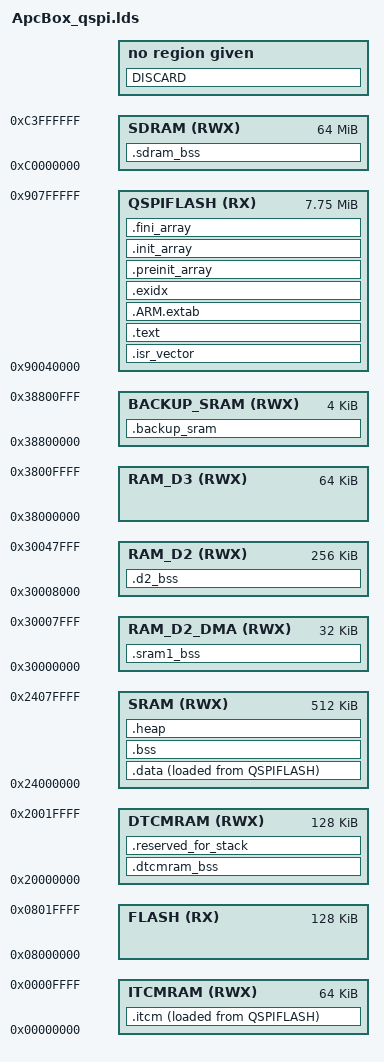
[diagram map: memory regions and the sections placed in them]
/* libDaisy's STM32H750IB_qspi.lds (v9.0.0) plus the .itcm section below. */
/* Generated by LinkerScriptGenerator [http://visualgdb.com/tools/LinkerScriptGenerator]
 * Target: STM32H750IB
 * The file is provided under the BSD license.
 * yeah okay but i also modified it a lot so like, give me some credit too mr BSD
 */

ENTRY(Reset_Handler)

MEMORY
{
	FLASH       (RX)  : ORIGIN = 0x08000000, LENGTH = 128K
	DTCMRAM     (RWX) : ORIGIN = 0x20000000, LENGTH = 128K
	SRAM        (RWX) : ORIGIN = 0x24000000, LENGTH = 512K
	RAM_D2_DMA  (RWX) : ORIGIN = 0x30000000, LENGTH = 32K
	RAM_D2      (RWX) : ORIGIN = 0x30008000, LENGTH = 256K
	RAM_D3      (RWX) : ORIGIN = 0x38000000, LENGTH = 64K
	BACKUP_SRAM (RWX) : ORIGIN = 0x38800000, LENGTH = 4K
	ITCMRAM     (RWX) : ORIGIN = 0x00000000, LENGTH = 64K
	SDRAM       (RWX) : ORIGIN = 0xc0000000, LENGTH = 64M
	QSPIFLASH   (RX)  : ORIGIN = 0x90040000, LENGTH = 7936K
}

_estack = 0x20020000;

SECTIONS
{
	.isr_vector :
	{
		. = ALIGN(4);
		KEEP(*(.isr_vector))
		. = ALIGN(4);
	} > QSPIFLASH

	/* ApcBox: what the audio callback runs, in the zero-wait code memory (ITCM)
	   and not read from the QSPI flash. The image sits in the flash and
	   ItcmLoad in main.cpp copies it down from .preinit_array, ahead of every
	   constructor. Only put here what nothing calls before that.
	   Starts 32 bytes in, so no function sits at address 0. Functions are
	   picked by section name (-ffunction-sections), nothing in the sources
	   says where they go. Must stay ahead of .text: first match wins. */
	.itcm :
	{
		. = . + 32;
		. = ALIGN(4);
		_sitcm = .;
		*main.o(.text.*AudioCallback*)
		*engine.o(.text.*6Engine7ProcessE* .text.*ProcessPerfFx* .text.*6Engine6OnStep* .text.*StartVoice*)
		*engine.o(.text.*AcidVoice* .text.*AcidStep* .text.*AcidLiveEvents* .text.*PerfFxEdges*)
		*engine.o(.text.*UpdateBlockParams* .text.*HandleRequests* .text.*StepLength* .text.*CaptureRead*)
		*engine.o(.text.*LiveHit* .text.*LiveRecStep* .text.*6Engine5Click*)
		*usbdev.o(.text.*AudioPush*)
		*libdaisy.a:audio.o(.text.*InternalCallback*)
		*libdaisy.a:sai.o(.text.*InternalCallback* .text.DMA1_Stream* .text.HAL_SAI_*Cplt*)
		*libdaisy.a:stm32h7xx_hal_sai.o(.text.SAI_DMA* .text.HAL_SAI_*Callback)
		*libdaisy.a:stm32h7xx_hal_dma.o(.text.HAL_DMA_IRQHandler)
		*libdaisy.a:sai.o(.text.*9SaiHandle9GetOffsetEv .text.*9SaiHandle9GetConfigEv)
		*libdaisy.a:system.o(.text.*6System7GetTickEv .text.*6System5GetUsEv)
		*libdaisy.a:tim.o(.text.*11TimerHandle7GetTickEv .text.*11TimerHandle5GetUsEv .text.*11TimerHandle4Impl7GetTickEv .text.*11TimerHandle4Impl5GetUsEv)
		*libdaisysp.a:svf.o(.text.*3Svf7Process* .text.*SetFreq* .text.*SetRes*)
		*engine.o(.text.*2ab6Reverb7Process* .text.*2ab6Reverb17NextRandomLineseg*)
		*(.text.expf .text.powf .text.sinf .text.cosf .text.lrintf .text.exp2f .text.sqrtf .text.__ieee754_sqrtf)
		*libm_a-k_cos.o(.text*)
		*libm_a-k_sin.o(.text*)
		. = ALIGN(4);
		_eitcm = .;
	} > ITCMRAM AT > QSPIFLASH
	/* where _sitcm's bytes sit in the flash (the section starts 32 bytes before it) */
	_siitcm = LOADADDR(.itcm) + (_sitcm - ADDR(.itcm));

	.text :
	{
		. = ALIGN(4);
		_stext = .;

		*(.text)
		*(.text*)
		*(.rodata)
		*(.rodata*)
		*(.glue_7)
		*(.glue_7t)
		KEEP(*(.init))
		KEEP(*(.fini))
		. = ALIGN(4);
		_etext = .;

	} > QSPIFLASH

	.ARM.extab :
	{
		. = ALIGN(4);
		*(.ARM.extab)
		*(.gnu.linkonce.armextab.*)
		. = ALIGN(4);
	} > QSPIFLASH

	.exidx :
	{
		. = ALIGN(4);
		PROVIDE(__exidx_start = .);
		*(.ARM.exidx*)
		. = ALIGN(4);
		PROVIDE(__exidx_end = .);
	} > QSPIFLASH

	.ARM.attributes 0 : { *(.ARM.attributes) }

	.preinit_array :
	{
		PROVIDE_HIDDEN(__preinit_array_start = .);
		KEEP(*(.preinit_array*))
		PROVIDE_HIDDEN(__preinit_array_end = .);
	} > QSPIFLASH

	.init_array :
	{
		PROVIDE_HIDDEN(__init_array_start = .);
		KEEP(*(SORT(.init_array.*)))
		KEEP(*(.init_array*))
		PROVIDE_HIDDEN(__init_array_end = .);
	} > QSPIFLASH

	.fini_array :
	{
		PROVIDE_HIDDEN(__fini_array_start = .);
		KEEP(*(.fini_array*))
		KEEP(*(SORT(.fini_array.*)))
		PROVIDE_HIDDEN(__fini_array_end = .);
	} > QSPIFLASH

	.sram1_bss (NOLOAD) :
	{
		. = ALIGN(4);
		_ssram1_bss = .;

		PROVIDE(__sram1_bss_start__ = _sram1_bss);
		*(.sram1_bss)
		*(.sram1_bss*)
		. = ALIGN(4);
		_esram1_bss = .;

		PROVIDE(__sram1_bss_end__ = _esram1_bss);
	} > RAM_D2_DMA

	.data :
	{
		. = ALIGN(4);
		_sdata = .;

		PROVIDE(__data_start__ = _sdata);
		*(.data)
		*(.data*)
		. = ALIGN(4);
		_edata = .;

		PROVIDE(__data_end__ = _edata);
	} > SRAM AT > QSPIFLASH

	_sidata = LOADADDR(.data);

	.bss (NOLOAD) :
	{
		. = ALIGN(4);
		_sbss = .;

		PROVIDE(__bss_start__ = _sbss);
		*(.bss)
		*(.bss*)
		*(COMMON)
		. = ALIGN(4);
		_ebss = .;

		PROVIDE(__bss_end__ = _ebss);
	} > SRAM

	.dtcmram_bss (NOLOAD) :
	{
		. = ALIGN(4);
		_sdtcmram_bss = .;

		PROVIDE(__dtcmram_bss_start__ = _sdtcmram_bss);
		*(.dtcmram_bss)
		*(.dtcmram_bss*)
		. = ALIGN(4);
		_edtcmram_bss = .;

		PROVIDE(__dtcmram_bss_end__ = _edtcmram_bss);
	} > DTCMRAM

	/*
	.sdram_text :
	{
		. = ALIGN(4);
		_ssdram_text = .;

		PROVIDE(__sdram_text_start = _ssdram_text);
		*(.sdram_text)
		*(.sdram_text*)
		. = ALIGN(4);
		_esdram_text = .;

		PROVIDE(__sdram_text_end = _esdram_text);
	} > SDRAM AT >FLASH
	_sisdram_text = LOADADDR(.sdram_text);
	*/

	.sdram_bss (NOLOAD) :
	{
		. = ALIGN(4);
		_ssdram_bss = .;

		PROVIDE(__sdram_bss_start = _ssdram_bss);
		*(.sdram_bss)
		*(.sdram_bss*)
		. = ALIGN(4);
		_esdram_bss = .;

		PROVIDE(__sdram_bss_end = _esdram_bss);
	} > SDRAM

	.backup_sram (NOLOAD) :
	{
		. = ALIGN(4);
		_sbackup_sram = .;

		PROVIDE(__backup_sram_start = _sbackup_sram);
		*(.backup_sram)
		*(.backup_sram*)
		. = ALIGN(4);
		_ebackup_sram = .;

		PROVIDE(__backup_sram_end = _ebackup_sram);
	} > BACKUP_SRAM


    /* .qspiflash_text :
	{
		. = ALIGN(4);
		_sqspiflash_text = .;

		PROVIDE(__qspiflash_text_start = _sqspiflash_text);
		*(.qspiflash_text)
		*(.qspiflash_text*)
		. = ALIGN(4);
		_eqspiflash_text = .;

		PROVIDE(__qspiflash_text_end = _eqspiflash_text);
	} > QSPIFLASH

	.qspiflash_data :
	{
		. = ALIGN(4);
		_sqspiflash_data = .;

		PROVIDE(__qspiflash_data_start = _sqspiflash_data);
		*(.qspiflash_data)
		*(.qspiflash_data*)
		. = ALIGN(4);
		_eqspiflash_data = .;

		PROVIDE(__qspiflash_data_end = _eqspiflash_data);
	} > QSPIFLASH

	.qspiflash_bss (NOLOAD) :
	{
		. = ALIGN(4);
		_sqspiflash_bss = .;

		PROVIDE(__qspiflash_bss_start = _sqspiflash_bss);
		*(.qspiflash_bss)
		*(.qspiflash_bss*)
		. = ALIGN(4);
		_eqspiflash_bss = .;

		PROVIDE(__qspiflash_bss_end = _eqspiflash_bss);
	} > QSPIFLASH */

	.heap (NOLOAD) :
	{
		. = ALIGN(4);
		PROVIDE(__heap_start__ = .);
		PROVIDE(__heap_start = .);
		KEEP(*(.heap))
		. = ALIGN(4);
		PROVIDE(__heap_end = .);
		PROVIDE(__heap_end__ = .);
	} > SRAM

	PROVIDE(end = .);

	/* ApcBox: big things that want internal RAM but not the main one. D2 RAM,
	   256 KB, on at start-up (system_stm32h7xx.c). Not zeroed: whoever puts
	   something here sets it up itself. */
	.d2_bss (NOLOAD) :
	{
		. = ALIGN(8);
		*(.d2_bss)
		*(.d2_bss.*)
		. = ALIGN(8);
	} > RAM_D2

	.reserved_for_stack (NOLOAD) :
	{
		. = ALIGN(4);
		PROVIDE(__reserved_for_stack_start__ = .);
		KEEP(*(.reserved_for_stack))
		. = ALIGN(4);
		PROVIDE(__reserved_for_stack_end__ = .);
	} > DTCMRAM

    DISCARD :
    {
        libc.a ( * )
        libm.a ( * )
        libgcc.a ( * )
    }

}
